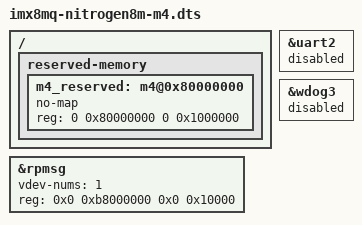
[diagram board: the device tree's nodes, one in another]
// SPDX-License-Identifier: (GPL-2.0+ OR MIT)
/*
 * Copyright 2018 Boundary Devices
 */

#include "imx8mq-nitrogen8m.dts"

/ {
	reserved-memory {
		#address-cells = <2>;
		#size-cells = <2>;
		ranges;

		m4_reserved: m4@0x80000000 {
			no-map;
			reg = <0 0x80000000 0 0x1000000>;
		};

	};
};

&rpmsg{
	/*
	 * 64K for one rpmsg instance:
	 * --0xb8000000~0xb800ffff: pingpong
	 */
	vdev-nums = <1>;
	reg = <0x0 0xb8000000 0x0 0x10000>;
	status = "okay";
};

&uart2 {
	status = "disabled";
};

&wdog3{
	status = "disabled";
};
